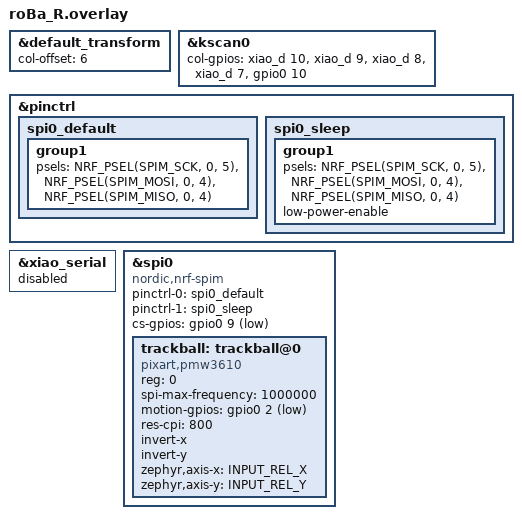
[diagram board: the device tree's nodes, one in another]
#include "roBa.dtsi"

&default_transform {
    col-offset = <6>;
};

&kscan0 {
        col-gpios
            = <&xiao_d 10 GPIO_ACTIVE_HIGH>
            , <&xiao_d 9 GPIO_ACTIVE_HIGH>
            , <&xiao_d 8 GPIO_ACTIVE_HIGH>
            , <&xiao_d 7 GPIO_ACTIVE_HIGH>
            , <&gpio0 10 GPIO_ACTIVE_HIGH>
            ;
};

&pinctrl {
    spi0_default: spi0_default {
        group1 {
            psels = <NRF_PSEL(SPIM_SCK, 0, 5)>,    // SCLK: P0.05
                <NRF_PSEL(SPIM_MOSI, 0, 4)>,       // MOSI: P0.04 (SDIO - bidirectional for 3-wire SPI)
                <NRF_PSEL(SPIM_MISO, 0, 4)>;       // MISO: P0.04 (SDIO - same pin for 3-wire SPI mode)
        };
    };

    spi0_sleep: spi0_sleep {
        group1 {
            psels = <NRF_PSEL(SPIM_SCK, 0, 5)>,    // SCLK: P0.05
                <NRF_PSEL(SPIM_MOSI, 0, 4)>,       // MOSI: P0.04 (SDIO)
                <NRF_PSEL(SPIM_MISO, 0, 4)>;       // MISO: P0.04 (SDIO - same pin for 3-wire SPI)
            low-power-enable;
        };
    };
};

&xiao_serial { status = "disabled"; };

&spi0 {
    status = "okay";
    compatible = "nordic,nrf-spim";
    pinctrl-0 = <&spi0_default>;
    pinctrl-1 = <&spi0_sleep>;
    pinctrl-names = "default", "sleep";
    cs-gpios = <&gpio0 9 GPIO_ACTIVE_LOW>;

    trackball: trackball@0 {
        status = "okay";
        compatible = "pixart,pmw3610";
        reg = <0>;
        spi-max-frequency = <1000000>;  // Reduced from 2MHz for better stability
        motion-gpios = <&gpio0 2 (GPIO_ACTIVE_LOW | GPIO_PULL_UP)>;
        res-cpi = <800>;
        invert-x;
        invert-y;
        // smart-mode; // Disabled - can cause erratic/teleporting behavior
        zephyr,axis-x = <INPUT_REL_X>;
        zephyr,axis-y = <INPUT_REL_Y>;
    };
};
